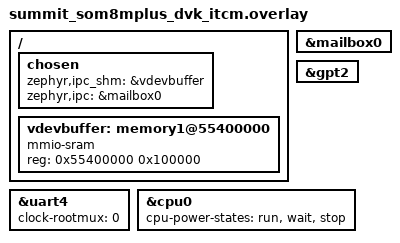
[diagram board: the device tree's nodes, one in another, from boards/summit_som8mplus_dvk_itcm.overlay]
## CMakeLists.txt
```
#
# Copyright (c) 2022 Laird Connectivity
#
# SPDX-License-Identifier: Apache-2.0
#

cmake_minimum_required(VERSION 3.20.0)

# Prepend the additional boards directory but still allow the original Zephyr
# boards directory to be used with lower priority
list(PREPEND BOARD_ROOT ${CMAKE_CURRENT_LIST_DIR}/../../)

set(MCUX_SDK_PROJECT_NAME app)

find_package(Zephyr REQUIRED HINTS $ENV{ZEPHYR_BASE})
project("Low Power Wakeup Example")

target_sources(app PRIVATE
	${CMAKE_SOURCE_DIR}/src/main.c
	${CMAKE_SOURCE_DIR}/src/empty_rsc_table.c
	${CMAKE_SOURCE_DIR}/src/lpm.c
)

include_directories(
	${CMAKE_SOURCE_DIR}/include
)
```

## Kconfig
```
#
# Copyright (c) 2022 Laird Connectivity
#
# SPDX-License-Identifier: Apache-2.0
#

menu "Low Power Wakeup Example"

config RPMSG_LITE_RESOURCE_TABLE
	bool "Co-processor resource table"
	help
	  Add the resource table in the generated binary. This table is
	  compatible with linux remote proc framework and RPMsg-Lite library.

config RPMSG_LITE_IPC_DEV_NAME
	string "RPMsg-Lite IPC device name"
	default "MAILBOX_0"

endmenu

module = MAIN
module-str = MAIN
source "subsys/logging/Kconfig.template.log_config"

source "Kconfig.zephyr"
```

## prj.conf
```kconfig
CONFIG_RPMSG_LITE_RESOURCE_TABLE=y
CONFIG_IPM=y
CONFIG_HEAP_MEM_POOL_SIZE=16384
CONFIG_IPM_IMX_REV2=y
CONFIG_IPM_IMX_MAX_DATA_SIZE_4=y
CONFIG_HAVE_CUSTOM_LINKER_SCRIPT=y
CONFIG_CUSTOM_LINKER_SCRIPT="linker.ld"
CONFIG_PM=y
CONFIG_COUNTER=y
CONFIG_LOG=y
CONFIG_MAIN_LOG_LEVEL_DBG=y
# CONFIG_GPIO is not set
CONFIG_PRINTK=y
CONFIG_SHELL=y
CONFIG_INIT_STACKS=y
CONFIG_THREAD_STACK_INFO=y
CONFIG_KERNEL_SHELL=y
CONFIG_THREAD_MONITOR=y
CONFIG_BOOT_BANNER=n
CONFIG_THREAD_NAME=y
CONFIG_DEVICE_SHELL=y
CONFIG_POSIX_CLOCK=y
CONFIG_DATE_SHELL=y
CONFIG_THREAD_RUNTIME_STATS=y
CONFIG_THREAD_RUNTIME_STATS_USE_TIMING_FUNCTIONS=y
CONFIG_DEVMEM_SHELL=n
CONFIG_AHB_CLOCK_ROOT_SYSTEM_PLL1_DIV6=y
CONFIG_PM_POLICY_APP=y
```

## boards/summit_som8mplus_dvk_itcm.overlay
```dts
/*
 * Copyright (c) 2022, Laird Connectivity
 *
 * SPDX-License-Identifier: Apache-2.0
 */

/ {
	chosen {
		/*
		 * shared memory reserved for the inter-processor communication
		 */
		zephyr,ipc_shm = &vdevbuffer;
		zephyr,ipc = &mailbox0;
	};

	vdevbuffer: memory1@55400000 {
		compatible = "mmio-sram";
		reg = <0x55400000 0x100000>;
	};
};

&mailbox0 {
	status = "okay";
};

&gpt2 {
	status = "okay";
};

&uart4 {
	clock-rootmux = <0>;
};

&cpu0 {
	cpu-power-states = <&run &wait &stop>;
};
```

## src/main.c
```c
/*
 * Copyright (c) 2022 Laird Connectivity
 *
 * SPDX-License-Identifier: Apache-2.0
 */

#include "low_power_wakeup.h"
#include <device.h>
#include <pm/pm.h>

LOG_MODULE_REGISTER(main, LOG_LEVEL_INF);

/* Definitions */
#define PM_MIN_TICKS 2
#define MAX_NUM_PLLS 39

/* Globals */
static const struct device *ipm_handle;
volatile bool wakeup_a_core_shell_flag = false;

extern void copy_resource_table();

/* Code */

/**
 * @brief Perform peripheral access configuration via the RDC.
 *
 */
void rdc_configure_peripheral_access(void)
{
	rdc_domain_assignment_t assignment = { 0 };
	rdc_periph_access_config_t periph_config;

	assignment.domainId = M7_DOMAIN_ID;

	/* Only configure the RDC if the RDC peripheral write access is allowed. */
	if ((0x1U & RDC_GetPeriphAccessPolicy(RDC, kRDC_Periph_RDC, assignment.domainId)) != 0U) {
		RDC_GetDefaultPeriphAccessConfig(&periph_config);

		/* Give the A53 domain (domain0) access to the I2C3 and SAI3 peripherals. */
		periph_config.policy = RDC_ACCESS_POLICY(A53_DOMAIN_ID, kRDC_ReadWrite);
		periph_config.periph = kRDC_Periph_I2C3;
		RDC_SetPeriphAccessConfig(RDC, &periph_config);
		periph_config.periph = kRDC_Periph_SAI3;
		RDC_SetPeriphAccessConfig(RDC, &periph_config);
	}
}

/**
 * @brief Set the target power mode for the M7 core
 *
 * @param target_power_mode	Desired power mode for the M7 core
 */
void lpm_set_power_status(lpm_power_status_m7_t target_power_mode)
{
	gpc_lpm_config_t config;
	config.enCpuClk = false;
	config.enFastWakeUp = false;
	config.enDsmMask = false;
	config.enWfiMask = false;
	config.enVirtualPGCPowerdown = true;
	config.enVirtualPGCPowerup = true;
	switch (target_power_mode) {
	case LPM_M7_STATE_RUN:
		GPC->LPCR_M7 = GPC->LPCR_M7 & (~GPC_LPCR_M7_LPM0_MASK);
		break;
	case LPM_M7_STATE_WAIT:
		GPC_EnterWaitMode(GPC, &config);
		break;
	case LPM_M7_STATE_STOP:
		GPC_EnterStopMode(GPC, &config);
		break;
	default:
		break;
	}
}

/**
 * @brief Logic run before entering the LPM stop mode
 *
 */
void pre_sleep_processing(void)
{
}

/**
 * @brief Logic run after exiting the LPM stop mode
 *
 */
void post_sleep_processing(void)
{
}

/**
 * @brief Send a signal via the MU peripheral to wake up the A core.
 *
 */
void wakeup_a_core()
{
	int ret = 0;
	uint32_t msg = 2;

	LOG_INF("Sending signal to wake up the A core");
	ret = ipm_send(ipm_handle, 0, MU_CHANNEL, &msg, 1);
	if (ret != 0) {
		LOG_WRN("ipm_send failed! ret: %d", ret);
	}
}

/**
 * @brief Shell 'demo' command that prints the current board configuration.
 *
 * @param shell	Pointer to shell struct
 * @param argc	Number of arguments received
 * @param argv	Pointer to string array of arguments received
 *
 * @return	0 for success, otherwise a numerical error code
 */
static int cmd_demo_board(const struct shell *shell, size_t argc, char **argv)
{
	ARG_UNUSED(argc);
	ARG_UNUSED(argv);

	shell_print(shell, CONFIG_BOARD);

	return 0;
}

/**
 * @brief Shell 'version' command that prints the Zephyr kernel version.
 *
 * @param shell	Pointer to shell struct
 * @param argc	Number of arguments received
 * @param argv	Pointer to string array of arguments received
 *
 * @return	0 for success, otherwise a numerical error code
 */
static int cmd_version(const struct shell *shell, size_t argc, char **argv)
{
	ARG_UNUSED(argc);
	ARG_UNUSED(argv);

	shell_print(shell, "Zephyr version %s", KERNEL_VERSION_STRING);

	return 0;
}

/**
 * @brief Shell 'wakeup' command that triggers a signal to wake up the A core.
 *
 * @param shell	Pointer to shell struct
 * @param argc	Number of arguments received
 * @param argv	Pointer to string array of arguments received
 * @param data	Pointer to received data
 * 
 * @return	0 for success, otherwise a numerical error code
 */
static int cmd_wakeup_a_core(const struct shell *shell, size_t argc, char **argv, void *data)
{
	ARG_UNUSED(shell);
	ARG_UNUSED(argc);
	ARG_UNUSED(argv);
	ARG_UNUSED(data);

	lpm_increase_block_sleep_count();

	wakeup_a_core_shell_flag = true;

	lpm_decrease_block_sleep_count();

	return 0;
}

/* Configure available shell commands */
SHELL_STATIC_SUBCMD_SET_CREATE(sub_demo,
			       SHELL_CMD(board, NULL, "Show board name command.", cmd_demo_board),
			       SHELL_SUBCMD_SET_END /* Array terminated. */
);

SHELL_CMD_REGISTER(demo, &sub_demo, "Demo commands", NULL);

SHELL_CMD_ARG_REGISTER(version, NULL, "Show kernel version", cmd_version, 1, 0);

SHELL_CMD_ARG_REGISTER(wakeup, NULL, "Wakeup the A core", cmd_wakeup_a_core, 1, 0);

/**
 * @brief Polling timer timeout function which handles checking the state of the
 * wakeup_a_core_shell_flag, and then waking up the A core, if necessary.
 *
 * @param timer	Pointer to timer struct
 */
static void polling_timeout(struct k_timer *timer)
{
	bool issue_wakeup = false;

	ARG_UNUSED(timer);

	if (wakeup_a_core_shell_flag) {
		wakeup_a_core_shell_flag = false;
		issue_wakeup |= true;
	}

	if (issue_wakeup) {
		wakeup_a_core();
	}
}

/* Define polling timer */
K_TIMER_DEFINE(polling_timer, polling_timeout, NULL);

/**
 * @brief Application-specific override of the Power Management set state function
 *
 * @param info	Info on the requested next state
 */
void pm_power_state_set(struct pm_state_info info)
{
	/* Extract target GPC mode from the substate ID */
	uint32_t target_mode = (uint32_t)info.substate_id;
	/* Read current GPC mode */
	uint32_t current_mode = GPC_GetLpmMode(GPC);

	irq_unlock(0);

	if (target_mode == current_mode) {
		__DSB();
		__ISB();
		__WFI();
		return;
	}

	switch (target_mode) {
	case kGPC_RunMode:
		lpm_set_power_status(LPM_M7_STATE_RUN);
		break;
	case kGPC_WaitMode:
		lpm_set_power_status(LPM_M7_STATE_WAIT);
		pre_sleep_processing();
		ServiceFlagAddr = ServiceIdle;

		__DSB();
		__ISB();
		__WFI();

		ServiceFlagAddr = ServiceBusy;
		post_sleep_processing();
		lpm_set_power_status(LPM_M7_STATE_RUN);
		break;
	case kGPC_StopMode:
		lpm_set_power_status(LPM_M7_STATE_STOP);
		pre_sleep_processing();
		ServiceFlagAddr = ServiceIdle;

		__DSB();
		__ISB();
		__WFI();

		ServiceFlagAddr = ServiceBusy;
		post_sleep_processing();
		lpm_set_power_status(LPM_M7_STATE_RUN);
		break;
	default:
		LOG_ERR("Unknown power state requested");
		return;
	}
}

/**
 * @brief Application-specific override of the Power Management power state exit handler function
 *
 * @param info	Info on the state that is currently being exited
 */
void pm_power_state_exit_post_ops(struct pm_state_info info)
{
	ARG_UNUSED(info);
}

/**
 * @brief Application-specific Power Management state management policy
 *
 * @param ticks			The number of remaining ticks before the system wakes
 * @return struct pm_state_info	Next power state
 */
struct pm_state_info pm_policy_next_state(int32_t ticks)
{
	/*
	 * If the available PM_MIN_TICKS is less than 2 or sleep isn't allowed, then just stay in
	 * the 'active' state. Otherwise, move to the 'wait' state.
	 */
	if (ticks >= PM_MIN_TICKS && lpm_allow_sleep()) {
		return (struct pm_state_info){ PM_STATE_SUSPEND_TO_IDLE, kGPC_WaitMode, 0 };
	} else {
		return (struct pm_state_info){ PM_STATE_ACTIVE, kGPC_RunMode, 0 };
	}
}

/**
 * @brief Main function entry point
 *
 */
void main(void)
{
	uint32_t i = 0;

	/* Block LPM wait mode until initial setup is complete */
	lpm_increase_block_sleep_count();

	/* Use RDC to configure peripheral access */
	rdc_configure_peripheral_access();

	copy_resource_table();

	/*
	 * In order to wakeup M7 from LPM, all PLLCTRLs need to be set to
	 * "NeededRun"
	 */
	for (i = 0; i != MAX_NUM_PLLS; i++) {
		CCM->PLL_CTRL[i].PLL_CTRL = kCLOCK_ClockNeededRun;
	}

	/*
	 * Set the ServiceFlag to ServiceBusy so that the A core does not attempt to stop the M7
	 * core when it enters into the DSM state.
	 */
	ServiceFlagAddr = ServiceBusy;

	LOG_INF("LOW POWER WAKEUP EXAMPLE");

	/* Setup the IPM (MU) peripheral */
	ipm_handle = device_get_binding(CONFIG_RPMSG_LITE_IPC_DEV_NAME);
	if (!ipm_handle) {
		LOG_ERR("Failed to find ipm device");
		return;
	}
	while (!device_is_ready(ipm_handle)) {
		LOG_ERR("MU is not ready");
		k_sleep(K_SECONDS(1));
	}

	/* Clear the terminal */
	shell_execute_cmd(shell_backend_uart_get_ptr(), "clear");

	/*
	 * Start polling timer.
	 */
	k_timer_start(&polling_timer, K_MSEC(POLLING_TIMER_PERIOD_MS),
		      K_MSEC(POLLING_TIMER_PERIOD_MS));

	/* Unblock LPM wait mode and sleep the main thread */
	lpm_decrease_block_sleep_count();
	k_sleep(K_FOREVER);
}
```

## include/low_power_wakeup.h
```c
/*
 * Copyright (c) 2022 Laird Connectivity
 *
 * SPDX-License-Identifier: Apache-2.0
 */

#ifndef LOW_POWER_WAKEUP_H
#define LOW_POWER_WAKEUP_H

#include <zephyr.h>
#include <sys/printk.h>
#include <logging/log.h>

#include <drivers/ipm.h>
#include <drivers/clock_control.h>

#include <shell/shell.h>
#include <shell/shell_uart.h>

#include <version.h>

#include <device.h>
#include "lpm.h"

#include "fsl_rdc.h"
#include "fsl_gpc.h"

/*******************************************************************************
 * Definitions
 ******************************************************************************/

#define M7_DOMAIN_ID (1U)
#define A53_DOMAIN_ID (0U)

/* Using SRC_GPR10 register to sync the tasks status with A core */
#define ServiceFlagAddr SRC->GPR10
/*
 * The flags, ServiceBusy and ServiceIdle, shows if the service task is running
 * or not. If the task is runing, A core should not put DDR in self-refresh mode
 * after A core enters supsend.
 */
#define ServiceBusy (0x5555U)
#define ServiceIdle (0x0U)

#define MU_CHANNEL 1U
#define POLLING_TIMER_PERIOD_MS 50

/*******************************************************************************
 * Types
 ******************************************************************************/

/* LPM state of M7 core */
typedef enum {
	LPM_M7_STATE_RUN,
	LPM_M7_STATE_WAIT,
	LPM_M7_STATE_STOP,
} lpm_power_status_m7_t;

/*******************************************************************************
 * Function Declarations
 ******************************************************************************/

void wakeup_a_core();

#endif // LOW_POWER_WAKEUP_H
```

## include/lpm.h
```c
/*
 * Copyright 2020 NXP
 * Copyright 2022, Laird Connectivity
 * All rights reserved.
 *
 * SPDX-License-Identifier: BSD-3-Clause
 */

#ifndef _LPM_H_
#define _LPM_H_

/*******************************************************************************
 * API
 ******************************************************************************/

#if defined(__cplusplus)
extern "C" {
#endif /* __cplusplus*/

/*!
 * @brief This function is used to increase the count of the block event.
 */
void lpm_increase_block_sleep_count(void);
/*!
 * @brief This function is used to decrease the count of the block event.
 */
void lpm_decrease_block_sleep_count(void);
/*!
 * @brief This function is used to judge if the system could enter low power mode.
 * @return Return true if there is no block event exists.
 */
bool lpm_allow_sleep(void);

#if defined(__cplusplus)
}
#endif /* __cplusplus*/
#endif /* _LPM_H_ */
```

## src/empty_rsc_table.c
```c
/*
 * Copyright (c) 2014, Mentor Graphics Corporation
 * All rights reserved.
 * Copyright (c) 2015 Xilinx, Inc. All rights reserved.
 * Copyright 2020 NXP.
 * All rights reserved.
 * Copyright (c) 2022 Laird Connectivity
 * All rights reserved.
 *
 * SPDX-License-Identifier: BSD-3-Clause
 *
 * This file provides the default empty resource table data structure
 * placed in the .resource_table section of the ELF file. This facilitates
 * basic support of remoteproc firmware loading from the Linux kernel.
 *
 * The .resource_table section has to be present in the ELF file in order
 * for the remoteproc ELF parser to accept the binary.
 *
 * See other multicore examples such as those utilizing rpmsg for a examples
 * of non-empty resource table.
 *
 */

#include <stdint.h>

#define VDEV0_VRING_BASE (0x55000000U)
#define RESOURCE_TABLE_OFFSET (0xFF000)

/* Place resource table in special ELF section */
#if defined(__ARMCC_VERSION) || defined(__GNUC__)
__attribute__((section(".resource_table")))
#elif defined(__ICCARM__)
#pragma location = ".resource_table"
#else
#error Compiler not supported!
#endif

const uint32_t resource_table[] = {
	/* Version */
	1,

	/* Number of table entries - resource table empty */
	0,

	/* reserved fields */
	0, 0
};

void copy_resource_table(void)
{
	/*
	* Resource table should be copied to VDEV0_VRING_BASE + RESOURCE_TABLE_OFFSET.
	* VDEV0_VRING_BASE is temperorily kept for backward compatibility, will be removed in future
	* release
	*/
	memcpy((void *)VDEV0_VRING_BASE, &resource_table, sizeof(resource_table));
	memcpy((void *)(VDEV0_VRING_BASE + RESOURCE_TABLE_OFFSET), &resource_table, sizeof(resource_table));
}
```

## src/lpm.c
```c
/*
 * Copyright 2020 NXP
 * Copyright 2022, Laird Connectivity
 * All rights reserved.
 *
 * SPDX-License-Identifier: BSD-3-Clause
 */

#include <zephyr.h>
#include "lpm.h"

/* If block envent exists, then do not allow M7 to enter low power mode. */
static uint32_t block_event_count = 0;

/*******************************************************************************
 * Code
 ******************************************************************************/

void lpm_increase_block_sleep_count(void)
{
	block_event_count++;
}

void lpm_decrease_block_sleep_count(void)
{
	block_event_count--;
}

bool lpm_allow_sleep(void)
{
	if (block_event_count) {
		return false;
	} else {
		return true;
	}
}
```
